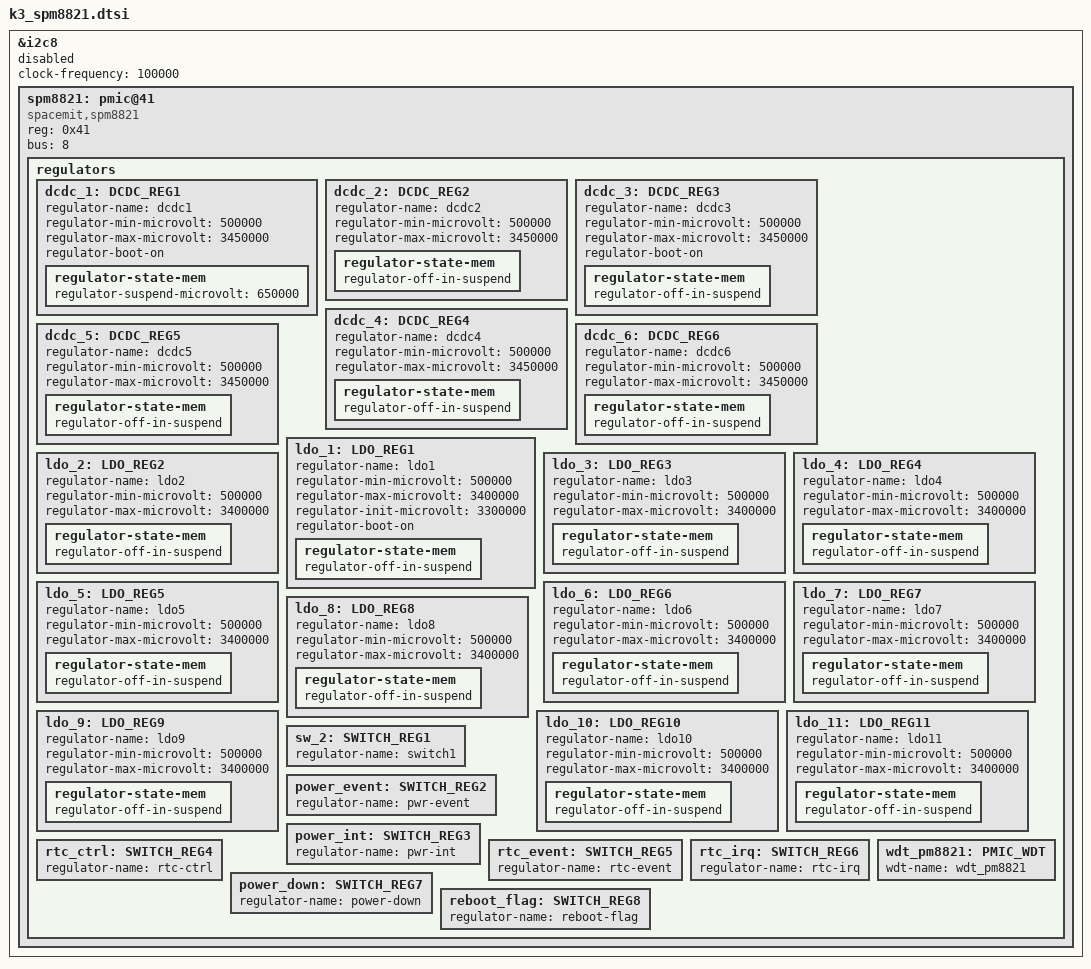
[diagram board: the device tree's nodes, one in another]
// SPDX-License-Identifier: (GPL-2.0 OR MIT)
/* Copyright (c) 2023 Spacemit, Inc */

&i2c8 {
	clock-frequency = <100000>;
	u-boot,dm-spl;
	status = "disabled";

	spm8821: pmic@41 {
		compatible = "spacemit,spm8821";
		reg = <0x41>;
		bus = <8>;
		u-boot,dm-spl;

		regulators {
			/* buck */
			dcdc_1: DCDC_REG1 {
				regulator-name = "dcdc1";
				regulator-min-microvolt = <500000>;
				regulator-max-microvolt = <3450000>;
				/* regulator-init-microvolt = <1050000>; */
				regulator-boot-on;
				u-boot,dm-spl;
				regulator-state-mem {
					regulator-suspend-microvolt = <650000>;
				};
			};

			dcdc_2: DCDC_REG2 {
				regulator-name = "dcdc2";
				regulator-min-microvolt = <500000>;
				regulator-max-microvolt = <3450000>;
				regulator-state-mem {
					regulator-off-in-suspend;
				};
			};

			dcdc_3: DCDC_REG3 {
				regulator-name = "dcdc3";
				regulator-min-microvolt = <500000>;
				regulator-max-microvolt = <3450000>;
				regulator-boot-on;
				u-boot,dm-spl;
				regulator-state-mem {
					regulator-off-in-suspend;
				};
			};

			dcdc_4: DCDC_REG4 {
				regulator-name = "dcdc4";
				regulator-min-microvolt = <500000>;
				regulator-max-microvolt = <3450000>;
				regulator-state-mem {
					regulator-off-in-suspend;
				};
			};

			dcdc_5: DCDC_REG5 {
				regulator-name = "dcdc5";
				regulator-min-microvolt = <500000>;
				regulator-max-microvolt = <3450000>;
				regulator-state-mem {
					regulator-off-in-suspend;
				};
			};

			dcdc_6: DCDC_REG6 {
				regulator-name = "dcdc6";
				regulator-min-microvolt = <500000>;
				regulator-max-microvolt = <3450000>;
				regulator-state-mem {
					regulator-off-in-suspend;
				};
			};

			/* aldo */
			ldo_1: LDO_REG1 {
				regulator-name = "ldo1";
				regulator-min-microvolt = <500000>;
				regulator-max-microvolt = <3400000>;
				regulator-init-microvolt = <3300000>;
				regulator-boot-on;
				u-boot,dm-spl;
				regulator-state-mem {
					regulator-off-in-suspend;
				};
			};

			ldo_2: LDO_REG2 {
				regulator-name = "ldo2";
				regulator-min-microvolt = <500000>;
				regulator-max-microvolt = <3400000>;
				regulator-state-mem {
					regulator-off-in-suspend;
				};
			};

			ldo_3: LDO_REG3 {
				regulator-name = "ldo3";
				regulator-min-microvolt = <500000>;
				regulator-max-microvolt = <3400000>;
				regulator-state-mem {
					regulator-off-in-suspend;
				};
			};

			ldo_4: LDO_REG4 {
				regulator-name = "ldo4";
				regulator-min-microvolt = <500000>;
				regulator-max-microvolt = <3400000>;
				regulator-state-mem {
					regulator-off-in-suspend;
				};
			};

			/* dldo */
			ldo_5: LDO_REG5 {
				regulator-name = "ldo5";
				regulator-min-microvolt = <500000>;
				regulator-max-microvolt = <3400000>;
				regulator-state-mem {
					regulator-off-in-suspend;
				};
			};

			ldo_6: LDO_REG6 {
				regulator-name = "ldo6";
				regulator-min-microvolt = <500000>;
				regulator-max-microvolt = <3400000>;
				regulator-state-mem {
					regulator-off-in-suspend;
				};
			};

			ldo_7: LDO_REG7 {
				regulator-name = "ldo7";
				regulator-min-microvolt = <500000>;
				regulator-max-microvolt = <3400000>;
				regulator-state-mem {
					regulator-off-in-suspend;
				};
			};

			ldo_8: LDO_REG8 {
				regulator-name = "ldo8";
				regulator-min-microvolt = <500000>;
				regulator-max-microvolt = <3400000>;
				regulator-state-mem {
					regulator-off-in-suspend;
				};
			};

			ldo_9: LDO_REG9 {
				regulator-name = "ldo9";
				regulator-min-microvolt = <500000>;
				regulator-max-microvolt = <3400000>;
				regulator-state-mem {
					regulator-off-in-suspend;
				};
			};

			ldo_10: LDO_REG10 {
				regulator-name = "ldo10";
				regulator-min-microvolt = <500000>;
				regulator-max-microvolt = <3400000>;
				regulator-state-mem {
					regulator-off-in-suspend;
				};
			};

			ldo_11: LDO_REG11 {
				regulator-name = "ldo11";
				regulator-min-microvolt = <500000>;
				regulator-max-microvolt = <3400000>;
				regulator-state-mem {
					regulator-off-in-suspend;
				};
			};

			sw_2: SWITCH_REG1 {
				regulator-name = "switch1";
			};

			power_event: SWITCH_REG2 {
				regulator-name = "pwr-event";
			};

			power_int: SWITCH_REG3 {
				regulator-name = "pwr-int";
			};

			rtc_ctrl: SWITCH_REG4 {
				regulator-name = "rtc-ctrl";
			};

			rtc_event: SWITCH_REG5 {
				regulator-name = "rtc-event";
			};

			rtc_irq: SWITCH_REG6 {
				regulator-name = "rtc-irq";
			};

			power_down: SWITCH_REG7 {
				regulator-name = "power-down";
			};

			reboot_flag: SWITCH_REG8 {
				regulator-name = "reboot-flag";
			};

			wdt_pm8821: PMIC_WDT {
				wdt-name = "wdt_pm8821";
			};
		};
	};
};
